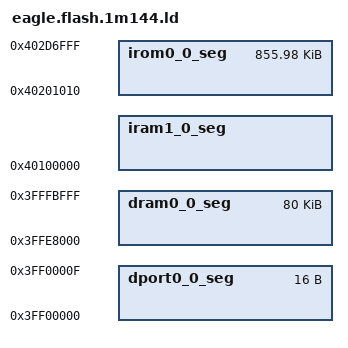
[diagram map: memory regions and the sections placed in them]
/* Flash Split for 1M chips */
/* sketch @0x40200000 (~855KB) (876528B) */
/* empty  @0x402D5FF0 (~4KB) (4112B) */
/* spiffs @0x402D7000 (~144KB) (147456B) */
/* eeprom @0x402FB000 (4KB) */
/* rfcal  @0x402FC000 (4KB) */
/* wifi   @0x402FD000 (12KB) */

MEMORY
{
  dport0_0_seg :                        org = 0x3FF00000, len = 0x10
  dram0_0_seg :                         org = 0x3FFE8000, len = 0x14000
  iram1_0_seg :                         org = 0x40100000, len = MMU_IRAM_SIZE
  irom0_0_seg :                         org = 0x40201010, len = 0xd5ff0
}

PROVIDE ( _FS_start = 0x402D7000 );
PROVIDE ( _FS_end = 0x402FB000 );
PROVIDE ( _FS_page = 0x100 );
PROVIDE ( _FS_block = 0x1000 );
PROVIDE ( _EEPROM_start = 0x402fb000 );
/* The following symbols are DEPRECATED and will be REMOVED in a future release */
PROVIDE ( _SPIFFS_start = 0x402D7000 );
PROVIDE ( _SPIFFS_end = 0x402FB000 );
PROVIDE ( _SPIFFS_page = 0x100 );
PROVIDE ( _SPIFFS_block = 0x1000 );

INCLUDE "local.eagle.app.v6.common.ld"
